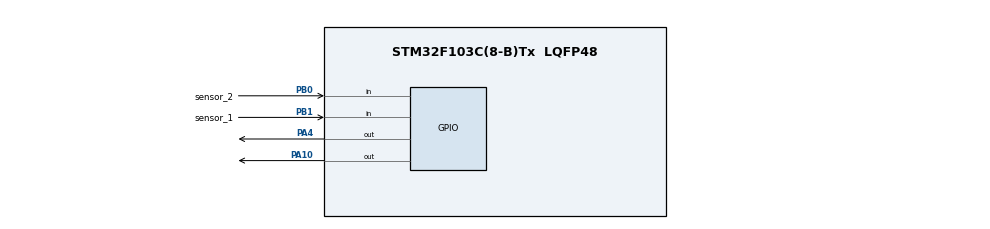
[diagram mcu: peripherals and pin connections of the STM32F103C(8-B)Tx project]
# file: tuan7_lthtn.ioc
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Mcu.Family=STM32F1
Mcu.Name=STM32F103C(8-B)Tx
Mcu.Package=LQFP48
NVIC.PriorityGroup=NVIC_PRIORITYGROUP_4
PA10.Signal=GPIO_Output
PA4.Signal=GPIO_Output
PB0.GPIO_Label=sensor_2
PB0.GPIO_PuPd=GPIO_PULLUP
PB0.Signal=GPIO_Input
PB1.GPIO_Label=sensor_1
PB1.Signal=GPIO_Input
PD0-OSC_IN.Mode=HSE-External-Oscillator
PD0-OSC_IN.Signal=RCC_OSC_IN
PD1-OSC_OUT.Mode=HSE-External-Oscillator
PD1-OSC_OUT.Signal=RCC_OSC_OUT
ProjectManager.HeapSize=0x200
ProjectManager.StackSize=0x400
ProjectManager.TargetToolchain=STM32CubeIDE
RCC.AHBFreq_Value=72000000
RCC.APB1CLKDivider=RCC_HCLK_DIV2
RCC.APB1Freq_Value=36000000
RCC.APB1TimFreq_Value=72000000
RCC.APB2Freq_Value=72000000
RCC.APB2TimFreq_Value=72000000
RCC.HCLKFreq_Value=72000000
RCC.PLLMUL=RCC_PLL_MUL9
RCC.PLLSourceVirtual=RCC_PLLSOURCE_HSE
RCC.SYSCLKFreq_VALUE=72000000
RCC.SYSCLKSource=RCC_SYSCLKSOURCE_PLLCLK
RCC.USBFreq_Value=72000000
board=custom

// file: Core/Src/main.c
/* USER CODE BEGIN Header */
/**
  ******************************************************************************
  * @file           : main.c
  * @brief          : Main program body
  ******************************************************************************
  * @attention
  *
  * Copyright (c) 2023 STMicroelectronics.
  * All rights reserved.
  *
  * This software is licensed under terms that can be found in the LICENSE file
  * in the root directory of this software component.
  * If no LICENSE file comes with this software, it is provided AS-IS.
  *
  ******************************************************************************
  */
/* USER CODE END Header */
#include "main.h"
#include "led_module.h"

void SystemClock_Config(void);
static void MX_GPIO_Init(void);

void delay() {
RCC->APB1ENR |= (1<<0);   /* enable TIM2 clock */
TIM2->PSC = 7200-1;  /* PSC = 7199 */
TIM2->ARR = 5000-1;
TIM2->SR = 0;  /* clear the UIF flag */
TIM2->CR1 = 1; /* up counting */
while((TIM2->SR & 1) == 0); /* wait until the UIF flag is set */
TIM2->CR1 = 0; /*stop counting */
}
int main(void)
{

  /* MCU Configuration--------------------------------------------------------*/

  /* Reset of all peripherals, Initializes the Flash interface and the Systick. */
  LL_APB2_GRP1_EnableClock(LL_APB2_GRP1_PERIPH_AFIO);
  LL_APB1_GRP1_EnableClock(LL_APB1_GRP1_PERIPH_PWR);

  /* System interrupt init*/
  NVIC_SetPriorityGrouping(NVIC_PRIORITYGROUP_4);

  /* SysTick_IRQn interrupt configuration */
  NVIC_SetPriority(SysTick_IRQn, NVIC_EncodePriority(NVIC_GetPriorityGrouping(),15, 0));

  /* Configure the system clock */
  SystemClock_Config();

  /* Initialize all configured peripherals */
  MX_GPIO_Init();

  /* Infinite loop */

  /* USER CODE BEGIN WHILE */
  //GPIOA->ODR |= (0b0000000000010000);
  init_State();
  LED_Ctrl_Init();
  while (1)
    {
      /* USER CODE END WHILE */
    //(GPIOA -> ODR) ^= (0b0000010000000000);
   // delay();
//	  if (((GPIOB -> IDR) & (1 << 0)) == 0)
//	  {
//		  delay();
//		  if (((GPIOB -> IDR) & (1 << 0)) == 0)
//		  {
//		  (GPIOA -> ODR) ^= (0b0000010000000000);
//		  }
//	}
		 state_Machine_Update();
  	//  if ((TIM2 -> SR & 1) != 0) (GPIOA -> ODR) |= (1 << 10);
  //		  while ((TIM2->SR & 1) == 0);
  //		 (GPIOA -> ODR) &= ~(1 << 10) ;
    }
  }

void SystemClock_Config(void)
{
  LL_FLASH_SetLatency(LL_FLASH_LATENCY_2);
  while(LL_FLASH_GetLatency()!= LL_FLASH_LATENCY_2)
  {
  }
  LL_RCC_HSE_Enable();

   /* Wait till HSE is ready */
  while(LL_RCC_HSE_IsReady() != 1)
  {

  }
  LL_RCC_PLL_ConfigDomain_SYS(LL_RCC_PLLSOURCE_HSE_DIV_1, LL_RCC_PLL_MUL_9);
  LL_RCC_PLL_Enable();

   /* Wait till PLL is ready */
  while(LL_RCC_PLL_IsReady() != 1)
  {

  }
  LL_RCC_SetAHBPrescaler(LL_RCC_SYSCLK_DIV_1);
  LL_RCC_SetAPB1Prescaler(LL_RCC_APB1_DIV_2);
  LL_RCC_SetAPB2Prescaler(LL_RCC_APB2_DIV_1);
  LL_RCC_SetSysClkSource(LL_RCC_SYS_CLKSOURCE_PLL);

   /* Wait till System clock is ready */
  while(LL_RCC_GetSysClkSource() != LL_RCC_SYS_CLKSOURCE_STATUS_PLL)
  {

  }
  LL_Init1msTick(72000000);
  LL_SetSystemCoreClock(72000000);
}

static void MX_GPIO_Init(void)
{
  LL_GPIO_InitTypeDef GPIO_InitStruct = {0};

  /* GPIO Ports Clock Enable */
  LL_APB2_GRP1_EnableClock(LL_APB2_GRP1_PERIPH_GPIOD);
  LL_APB2_GRP1_EnableClock(LL_APB2_GRP1_PERIPH_GPIOA);
  LL_APB2_GRP1_EnableClock(LL_APB2_GRP1_PERIPH_GPIOB);

  /**/
  LL_GPIO_ResetOutputPin(GPIOA, LL_GPIO_PIN_4|LL_GPIO_PIN_10);

  /**/
  GPIO_InitStruct.Pin = LL_GPIO_PIN_4|LL_GPIO_PIN_10;
  GPIO_InitStruct.Mode = LL_GPIO_MODE_OUTPUT;
  GPIO_InitStruct.Speed = LL_GPIO_SPEED_FREQ_LOW;
  GPIO_InitStruct.OutputType = LL_GPIO_OUTPUT_PUSHPULL;
  LL_GPIO_Init(GPIOA, &GPIO_InitStruct);

  /**/
  GPIO_InitStruct.Pin = sensor_2_Pin;
  GPIO_InitStruct.Mode = LL_GPIO_MODE_INPUT;
  GPIO_InitStruct.Pull = LL_GPIO_PULL_UP;
  LL_GPIO_Init(sensor_2_GPIO_Port, &GPIO_InitStruct);

  /**/
  GPIO_InitStruct.Pin = sensor_1_Pin;
  GPIO_InitStruct.Mode = LL_GPIO_MODE_FLOATING;
  LL_GPIO_Init(sensor_1_GPIO_Port, &GPIO_InitStruct);

}

void Error_Handler(void)
{
  __disable_irq();
  while (1)
  {
  }
}
